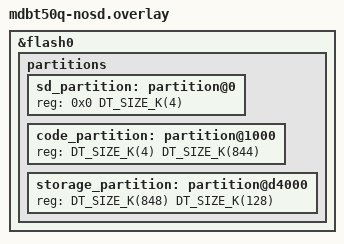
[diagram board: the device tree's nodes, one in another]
/delete-node/ &reserved_partition_0;
/delete-node/ &code_partition;
/delete-node/ &storage_partition;

&flash0 {
    partitions {
        sd_partition: partition@0 {
            reg = <0x0 DT_SIZE_K(4)>;
        };

        code_partition: partition@1000 {
            reg = <DT_SIZE_K(4) DT_SIZE_K(844)>;
        };

        storage_partition: partition@d4000 {
            reg = <DT_SIZE_K(848) DT_SIZE_K(128)>;
        };
    };
};
